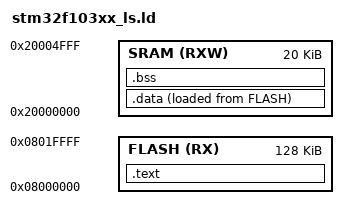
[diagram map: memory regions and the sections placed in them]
/* Linker Script by Matheus Souza (github.com/mfbsouza) */

ENTRY (Reset_Handler)

MEMORY
{
    FLASH (RX) : ORIGIN = 0x08000000, LENGTH = 128K
    SRAM (RXW) : ORIGIN = 0x20000000, LENGTH = 20K
}

SECTIONS
{
    .text : {
        *(.vectors)
        *(.init)
        *(.text)
        *(.rodata)
        . = ALIGN(4);
        _etext = .;
    }> FLASH

    .data : {
        _sdata = .;
        *(.data)
        . = ALIGN(4);
        _edata = .;
    }> SRAM AT> FLASH

    .bss : {
        _sbss = .;
        *(.bss)
        *(COMMON)
        . = ALIGN(4);
        _ebss = .;
    }> SRAM
}
